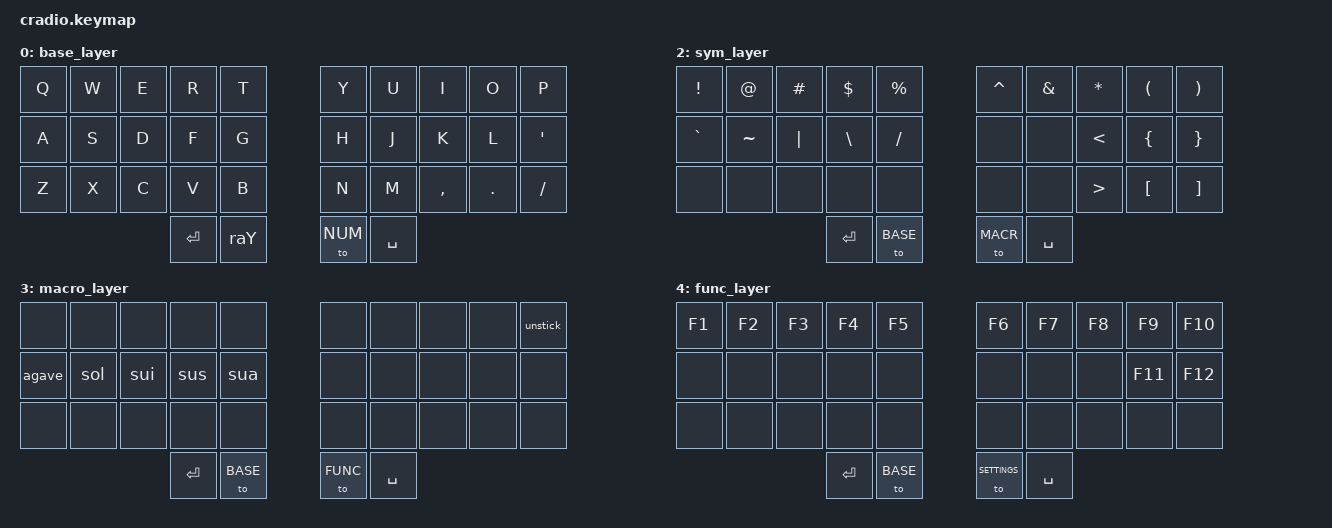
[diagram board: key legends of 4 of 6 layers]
/*
 * Copyright (c) 2020 The ZMK Contributors
 *
 * SPDX-License-Identifier: MIT
 * 
 * keymap by Alan Chapman - https://github.com/acchapm1/zmk-sweep-qwerty
 * Board - Ferris Sweep v2.2
 * Switches - Kailh Choc brown
 * 
 */

#include <behaviors.dtsi>
#include <dt-bindings/zmk/keys.h>
#include <dt-bindings/zmk/bt.h>

// Layer definitions
    #define BASE 0
    #define NUM 1
    #define SYM 2
    #define MACR 3
    #define FUNC 4
	#define SETTINGS 5
// -----------------

&mt {
    //  flavor = "tap-preferred";
    tapping_term_ms = <200>;
};
&sk {
    release-after-ms = <2000>;
    quick-release;
    /delete-property/ ignore-modifiers;
};
&caps_word {
    continue-list = <UNDERSCORE MINUS>;
};

// Aliases
	#define CW &caps_word
	#define BL &bootloader
    #define xxx &none
    #define ___ &trans
    #define iHOMsel RG(RS(LEFT))
    #define iENDsel RG(RS(RIGHT))
    #define selAll RG(A)
    #define mtRight LC(RIGHT)
    #define mtLeft LC(LEFT)
    #define coPy LG(C)
    #define pasTE LG(V)
    #define raY LA(SPACE)
    #define reDo RG(RS(Z))
    #define unDo RG(Z)
    #define tmuxKey L(B)
    #define bT0 BT_SEL 0
    #define bT1 BT_SEL 1
    #define bT2 BT_SEL 2
    #define bTNxt BT_NXT
    #define bTPrv BT_PRV
    #define bTClr BT_CLR
//    #define Lth1 &mt raY RETURN
//    #define Lth2 &mt SYM BACKSPACE
//    #define Rth1 &mt 
//    #define Rth2 
// -----------------

/ { 
    macros {
		unstick: unstick {
		    label = "ZM_unstick";
		    compatible = "zmk,behavior-macro";
		    #binding-cells = <0>;
		    bindings
			      = <&kp LSHIFT &kp RSHIFT &kp LCTRL &kp RCTRL &kp LALT &kp RALT &kp LGUI &kp RGUI>;
			  };
        agave: agave {
            label = "ZM_agave";
            compatible = "zmk,behavior-macro";
            #binding-cells = <0>;
            bindings 
                = <&kp A &kp G &kp A &kp V &kp E &kp RET>;
            };
        sol: sol {
            label = "ZM_sol";
            compatible = "zmk,behavior-macro";
            #binding-cells = <0>;
            bindings 
                = <&kp S &kp O &kp L &kp RET>;
            };
        sui: sui {
            label = "ZM_sui";
            compatible = "zmk,behavior-macro";
            #binding-cells = <0>;
            bindings 
                = <&kp COLON &kp S &kp U &kp I>;
            };        
        sus: sus {
            label = "ZM_sus";
            compatible = "zmk,behavior-macro";
            #binding-cells = <0>;
            bindings 
                = <&kp COLON &kp S &kp U &kp S>;
            };
        sua: sua {
            label = "ZM_sua";
            compatible = "zmk,behavior-macro";
            #binding-cells = <0>;
            bindings 
                = <&kp COLON &kp S &kp U &kp A>;
            };
		};
        // end macros

        // Combos Keys # Reference
        /*               KEY POSITIONS
        ╭────────────────────╮ ╭────────────────────╮
        │  0   1   2   3   4 │ │  5   6   7   8   9 │
        │ 10  11  12  13  14 │ │ 15  16  17  18  19 │
        │ 20  21  22  23  24 │ │ 25  26  27  28  29 │
        ╰───────╮     30  31 │ │ 32  33     ╭───────╯
                ╰────────────╯ ╰────────────╯      */
        combos {
          compatible = "zmk,combos";
            // Q W
            combo_esc {
            timeout-ms = <50>;
            key-positions = <0 1>;
            bindings = <&kp ESC>;
        };
            // A S
            combo_tab {
            timeout-ms = <50>;
            key-positions = <10 11>;
            bindings = <&kp TAB>;
        };
            // J K
            combo_ralt {
            timeout-ms = <50>;
            key-positions = <17 16>;
            bindings = <&kp RALT>;
        }; 
            // S D
            combo_lalt {
            timeout-ms = <50>;
            key-positions = <11 12>;
            bindings = <&kp LALT>;
        };  
            // D F
            combo_lgui {
            timeout-ms = <50>;
            key-positions = <12 13>;
            bindings = <&kp LGUI>;
        };
            // K L
            combo_rgui {
            timeout-ms = <50>;
            key-positions = <17 18>;
            bindings = <&kp RGUI>;
        };
            // both left thumb keys
			combo_settings {
			timeout-ms = <300>;
			key-positions = <30 31>;
			bindings = <&mo SETTINGS>;
		};  
            // C W
            combo_caps_word {
            timeout-ms = <50>;
            key-positions = <22 1>;
            bindings = <&caps_word>;
        };
            // V B
            combo_backspace {
            timeout-ms = <50>;
            key-positions = <23 24>;
            bindings = <&kp BACKSPACE>;
        };
    };
        keymap {
            compatible = "zmk,keymap";
         // Base Layer       
       	    base_layer {
            bindings = <
         //╭─────────────────────────────────────────────────────────────╮   ╭─────────────────────────────────────────────────────────────╮
         //│   Q      │    W       │    E      │    R      │     T       │   │    Y      │    U        │    I      │    O     │      P     │
		     &kp Q       &kp W        &kp E        &kp R       &kp T 			 &kp Y      &kp U         &kp I       &kp O        &kp P 
         //│   A      │    S       │    D      │    F      │    G        │   │    H      │    J        │    K      │    L     │     "      │
		     &kp A       &kp S        &kp D        &kp F      &kp G 			&kp H       &kp J         &kp K       &kp L      &kp SQT
         //│   Z      │      X     │      C    │     V     │      B      │   │     N     │     M       │     ,     │      .   │      /     │
		     &kp Z       &kp X        &kp C       &kp V        &kp B	   	     &kp N       &kp M       &kp COMMA     &kp DOT    &kp FSLH
         //╰────────────────────────────────╮     Enter    |  Raycast    │   │    NUM    |    SPACE    ╭───────────────────────────────────╯   
          				                        &kp ENTER     &kp raY  	        &to NUM    &kp SPACE 
         //                                 ╰────────────────────────────╯   ╰─────────────────────────╯ 
		    >;
		  };
         // Numbers and navigation
       	    num_layer {
		    bindings = <
         //╭─────────────────────────────────────────────────────────────╮   ╭─────────────────────────────────────────────────────────────╮
         //│     1     │    2    │     3    │       4       │       5    │   │    6       │    7       │    8      │    9      │    0      │
		      &kp N1      &kp N2     &kp N3      &kp N4       &kp N5   		    &kp N6       &kp N7        &kp N8     &kp N9      &kp N0 
		 //│  ALT      │   GUI   │   SHIFT  │         CRTL  │   RALT     │   │  Left      │    Down    │     UP    │    Right  │      "    │
		     &sk LALT   &sk LCMD    &sk LSHFT   &sk LCTRL     &sk RALT 		    &kp LEFT    &kp DOWN     &kp UP      &kp RIGHT    &kp DQT 
		 //│ CapsWord  │         │          │      ESC      │     TAB    │ 	 │    ~       │      =     │      +    │      -    │      \    │
		     &kp CW      &none     &none       &kp ESC        &kp TAB 	        &kp TILDE   &kp EQUAL    &kp PLUS    &kp MINUS    &kp BSLH 
         //╰────────────────────────────────╮    ENTER      │    BASE    │   │    SYM    │    SPACE    ╭───────────────────────────────────╯
					                           &kp ENTER       &to BASE   	    &to SYM     &kp SPACE 
         //                                 ╰────────────────────────────╯   ╰─────────────────────────╯                                            
		    >;
		  };
		 // Symbols layer
		    sym_layer {
		    bindings = <
         //╭─────────────────────────────────────────────────────────────╮   ╭─────────────────────────────────────────────────────────────╮
         //│     !     │     @     │    #    │         $    │       %    │   │    ^      │    &      │    *      │    (      │    )        │
		      &kp EXCL     &kp AT   &kp HASH     &kp DLLR     &kp PRCNT    	   &kp CARET    &kp AMPS   &kp STAR    &kp LPAR     &kp RPAR 
		 //│   `       │    ~      │    │    │    \         │       /    │   │           │           │    <      │    {      │    }        │
		    &kp GRAVE  &kp TILDE  &kp PIPE   &kp BSLH   &kp FSLH 			    &none      &none        &kp LT     &kp LBRC     &kp RBRC
		 //│           │           │         │              │            │ 	 │           │           │    >      │     [     │    ]        │
		      &none      &none      &none      &none      &none        			&none      &none        &kp GT      &kp LBKT    &kp RBKT
         //╰────────────────────────────────╮    ENTER      │    BASE    │   │    MACR   │    SPACE    ╭───────────────────────────────────╯
					                            &kp ENTER    &to BASE  	    	    &to MACR  &kp SPACE 
         //                                 ╰────────────────────────────╯   ╰─────────────────────────╯ 
		    >;
		  };
         // Macro
		    macro_layer {
		    bindings = <
         //╭─────────────────────────────────────────────────────────────╮   ╭─────────────────────────────────────────────────────────────╮
         //│          │           │          │              │            │   │            │           │           │           │  unstick   │
		      &none       &none       &none       &none         &none     		  &none       &none       &none       &none      &unstick
		 //│   Agave  │    Sol    │   :SUI   │    :SUS      │    :SUA    │   │            │           │           │           │            │
		      &agave      &sol        &sui        &sus          &sua   			  &none       &none       &none       &none       &none 
		 //│          │           │          │              │            │ 	 │            │           │           │           │            │ 
		      &none       &none       &none       &none         &none     		  &none       &none       &none       &none       &none  
         //╰────────────────────────────────╮     ENTER     │    BASE    │   │    FUNC    │   SPACE    ╭───────────────────────────────────╯
				  	                            &kp ENTER      &to BASE  	    &to FUNC    &kp SPACE 
         //                                 ╰────────────────────────────╯   ╰─────────────────────────╯ 
		    >;
		  };	
		 // Functions
		    func_layer {
		    bindings = <
         //╭─────────────────────────────────────────────────────────────╮   ╭─────────────────────────────────────────────────────────────╮
         //│   F1    │    F2    │    F3     │       F4   │      F5       │   │    F6       │    F7     │    F8    │     F9    │     F10    │
		     &kp F1    &kp F2      &kp F3       &kp F4        &kp F5  			  &kp F6      &kp F7      &kp F8      &kp F9     &kp F10
         //│         │          │           │            │               │   │             │           │          │   F11     │   F12      │
		    &none       &none       &none       &none       &none  			      &none      &none      &none        &kp F11    &kp F12
         //│         │          │           │            │               │ 	 │             │           │          │           │            │ 
		    &none       &none       &none       &none       &none  			      &none      &none      &none        &none      &none   
         //╰────────────────────────────────╮    ENTER      │    BASE    │   │    SETTINGS │   SPACE   ╭───────────────────────────────────╯  
					                            &kp ENTER      &to BASE  		  &to SETTINGS  &kp SPACE 
         //                                 ╰────────────────────────────╯   ╰─────────────────────────╯ 
		    >;
		  };	
         // Settings
		    ble_layer {
		    bindings = <
         //╭─────────────────────────────────────────────────────────────╮   ╭─────────────────────────────────────────────────────────────╮
         //│ BootLdr │           │          │     BT_CLR  │      BT 0    │   │           │            │           │           │            │
		     &kp BL     &none     &none        &bt BT_CLR       &bt bT0 		&none       &none         &none       &none        &none
         //│         │           │          │             │      BT 1    │   │           │            │           │           │            │
		      &none      &none       &none       &none         &bt bT1  	    &none       &none         &none       &none        &none 
         //│  BT_CLR │   BT_NXT  │  BT_PREV │             │      BT 2    │ 				  │         │         │         │         │         │ 
		    &bt bTClr   &bt bTNxt  &bt bTPrv    &none          &bt bT2  	    &none       &none         &none       &none        &none
         //╰────────────────────────────────╮    ENTER    │      BASE    │   │           │     SPACE   ╭───────────────────────────────────╯ 
					                            &kp ENTER        &to BASE 		&none       &kp SPACE 
         //                                 ╰────────────────────────────╯   ╰─────────────────────────╯
		    >;
		  };	
    };    
};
